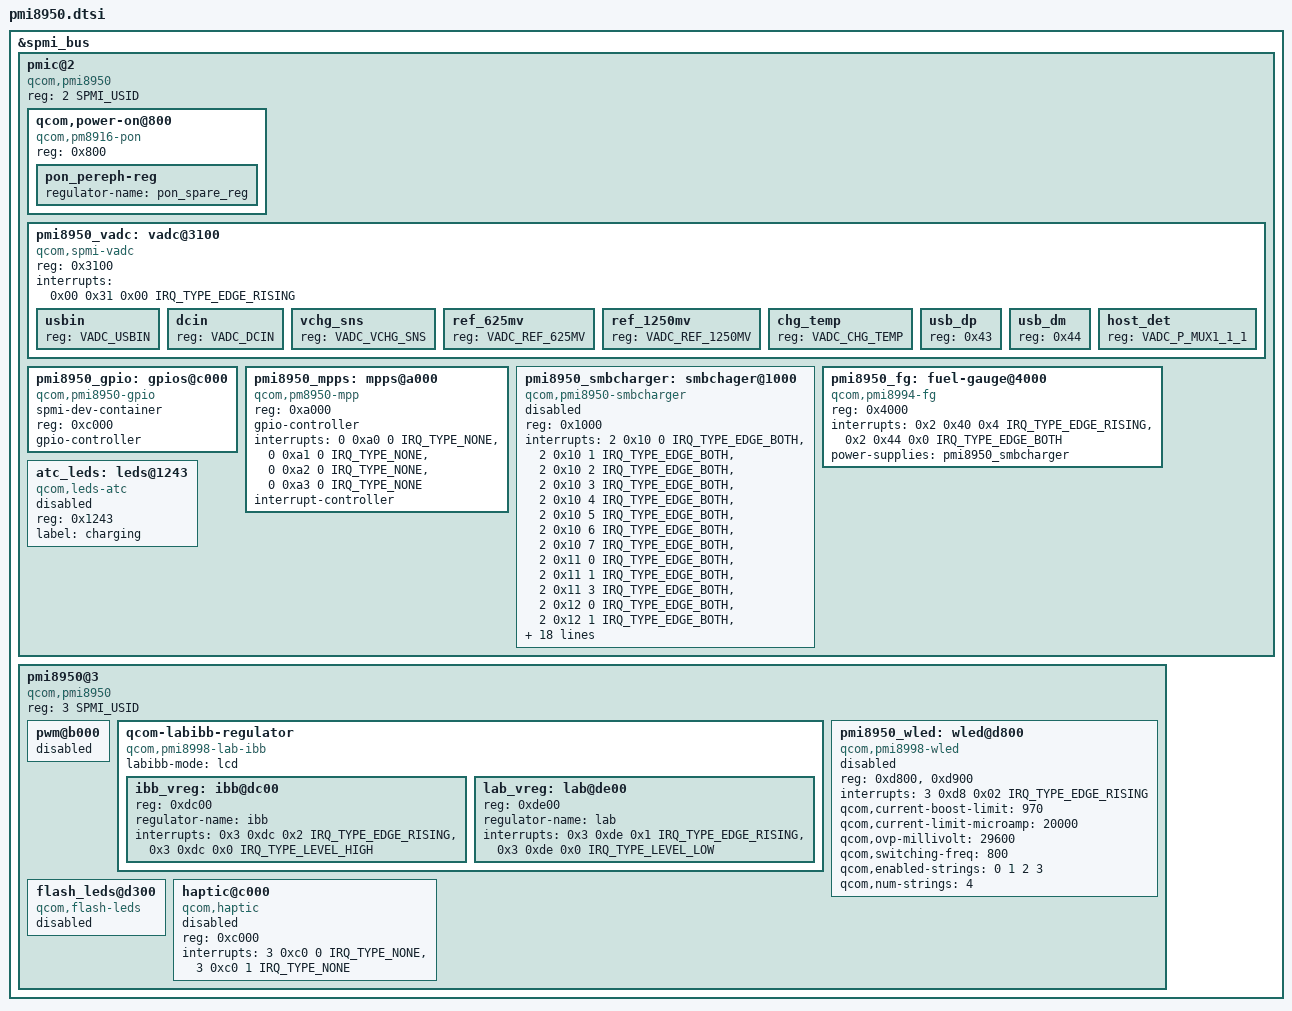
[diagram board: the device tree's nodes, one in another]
// SPDX-License-Identifier: GPL-2.0-only
/* Copyright (c) 2020, The Linux Foundation. All rights reserved.
 */
#include <dt-bindings/iio/qcom,spmi-vadc.h>
#include <dt-bindings/interrupt-controller/irq.h>
#include <dt-bindings/input/linux-event-codes.h>
#include <dt-bindings/spmi/spmi.h>

&spmi_bus {
	pmic@2 {
		compatible = "qcom,pmi8950", "qcom,spmi-pmic";
		reg = <2 SPMI_USID>;
		#address-cells = <1>;
		#size-cells = <0>;

		qcom,power-on@800 {
			compatible = "qcom,pm8916-pon"; //FIXME is this the correct driver
			reg = <0x800>;			//This pmic may be gen2 unlike 8916
			//qcom,secondary-pon-reset;
			//qcom,hard-reset-poweroff-type = <0x04>;
			pon_pereph-reg {
				//TODO:
				regulator-name = "pon_spare_reg";
			};
		};

		pmi8950_vadc: vadc@3100 {
			compatible = "qcom,spmi-vadc";
			reg = <0x3100>;
			interrupts = <0x00 0x31 0x00 IRQ_TYPE_EDGE_RISING>;
			#address-cells = <1>;
			#size-cells = <0>;
			#io-channel-cells = <1>;

			usbin {
				reg = <VADC_USBIN>;
			};

			dcin {
				reg = <VADC_DCIN>;
			};

			vchg_sns {
				reg = <VADC_VCHG_SNS>;
			};

			ref_625mv {
				reg = <VADC_REF_625MV>;
			};

			ref_1250mv {
				reg = <VADC_REF_1250MV>;
			};

			chg_temp {
				reg = <VADC_CHG_TEMP>;
			};

			usb_dp {
				//FIXME: Unsupported?
				reg = <0x43>;
			};

			usb_dm {
				//FIXME: Unsupported?
				reg = <0x44>;
			};

			host_det {
				//FIXME: Unsupported?
				reg = <VADC_P_MUX1_1_1>;
			};
		};

		pmi8950_gpio: gpios@c000 {
			spmi-dev-container;
			compatible = "qcom,pmi8950-gpio";
			reg = <0xc000>;

			gpio-controller;
			#gpio-cells = <2>;
			#address-cells = <1>;
			#size-cells = <0>;
		};

		pmi8950_mpps: mpps@a000 {
			compatible = "qcom,pm8950-mpp";
			reg = <0xa000>;
			gpio-controller;
			#gpio-cells = <2>;
			interrupts = <0 0xa0 0 IRQ_TYPE_NONE>,
				     <0 0xa1 0 IRQ_TYPE_NONE>,
				     <0 0xa2 0 IRQ_TYPE_NONE>,
				     <0 0xa3 0 IRQ_TYPE_NONE>;
			interrupt-controller;
			#interrupt-cells = <2>;
		};

		pmi8950_smbcharger: smbchager@1000 {
			compatible = "qcom,pmi8950-smbcharger";
			reg = <0x1000>;
			status = "disabled";
			interrupts = <2 0x10 0 IRQ_TYPE_EDGE_BOTH>,
					<2 0x10 1 IRQ_TYPE_EDGE_BOTH>,
					<2 0x10 2 IRQ_TYPE_EDGE_BOTH>,
					<2 0x10 3 IRQ_TYPE_EDGE_BOTH>,
					<2 0x10 4 IRQ_TYPE_EDGE_BOTH>,
					<2 0x10 5 IRQ_TYPE_EDGE_BOTH>,
					<2 0x10 6 IRQ_TYPE_EDGE_BOTH>,
					<2 0x10 7 IRQ_TYPE_EDGE_BOTH>,
					<2 0x11 0 IRQ_TYPE_EDGE_BOTH>,
					<2 0x11 1 IRQ_TYPE_EDGE_BOTH>,
					<2 0x11 3 IRQ_TYPE_EDGE_BOTH>,
					<2 0x12 0 IRQ_TYPE_EDGE_BOTH>,
					<2 0x12 1 IRQ_TYPE_EDGE_BOTH>,
					<2 0x12 2 IRQ_TYPE_EDGE_BOTH>,
					<2 0x12 3 IRQ_TYPE_EDGE_BOTH>,
					<2 0x12 4 IRQ_TYPE_EDGE_BOTH>,
					<2 0x12 5 IRQ_TYPE_EDGE_BOTH>,
					<2 0x12 6 IRQ_TYPE_EDGE_BOTH>,
					<2 0x12 7 IRQ_TYPE_EDGE_BOTH>,
					<0x2 0x13 0x0 IRQ_TYPE_EDGE_BOTH>,
					<0x2 0x13 0x1 IRQ_TYPE_EDGE_BOTH>,
					<0x2 0x13 0x2 IRQ_TYPE_EDGE_BOTH>,
					<0x2 0x13 0x5 IRQ_TYPE_EDGE_BOTH>,
					<0x2 0x14 0x0 IRQ_TYPE_EDGE_BOTH>,
					<0x2 0x14 0x1 IRQ_TYPE_EDGE_BOTH>,
					<0x2 0x16 0x0 IRQ_TYPE_EDGE_BOTH>,
					<0x2 0x16 0x1 IRQ_TYPE_EDGE_BOTH>,
					<0x2 0x16 0x2 IRQ_TYPE_EDGE_BOTH>,
					<0x2 0x16 0x3 IRQ_TYPE_EDGE_BOTH>,
					<0x2 0x16 0x4 IRQ_TYPE_EDGE_BOTH>,
					<0x2 0x16 0x5 IRQ_TYPE_EDGE_BOTH>;

			interrupt-names = "chg-error",
					"chg-inhibit",
					"chg-prechg-sft",
					"chg-complete-chg-sft",
					"chg-p2f-thr",
					"chg-rechg-thr",
					"chg-taper-thr",
					"chg-tcc-thr",
					"otg-fail",
					"otg-oc",
					"usbid-change",
					"batt-hot",
					"batt-warm",
					"batt-cold",
					"batt-cool",
					"batt-ov",
					"batt-low",
					"batt-missing",
					"batt-term-missing",
					"usbin-uv",
					"usbin-ov",
					"usbin-src-det",
					"aicl-done",
					"dcin-uv",
					"dcin-ov",
					"power-ok",
					"temp-shutdown",
					"wdog-timeout",
					"flash-fail",
					"otst2",
					"otst3";
		};

		pmi8950_fg: fuel-gauge@4000 {
			compatible = "qcom,pmi8994-fg";
			reg = <0x4000>;

			interrupts = <0x2 0x40 0x4 IRQ_TYPE_EDGE_RISING>,
				     <0x2 0x44 0x0 IRQ_TYPE_EDGE_BOTH>;
			interrupt-names = "soc-delta", "mem-avail";

			power-supplies = <&pmi8950_smbcharger>;
			status = "okay";
		};

		atc_leds: leds@1243 {
			reg = <0x1243>;
			compatible = "qcom,leds-atc";
			label = "charging";
			status = "disabled";
		};
	};

	pmi8950@3 {
		compatible = "qcom,pmi8950", "qcom,spmi-pmic";
		reg = <3 SPMI_USID>;
		#address-cells = <1>;
		#size-cells = <0>;

		pwm@b000 {
			status = "disabled";
		};

		qcom-labibb-regulator {
			compatible = "qcom,pmi8998-lab-ibb";
			labibb-mode = "lcd";
			#address-cells = <1>;
			#size-cells = <0>;

			ibb_vreg: ibb@dc00 {
				reg = <0xdc00>;
				regulator-name = "ibb";
				interrupts = <0x3 0xdc 0x2 IRQ_TYPE_EDGE_RISING>,
					     <0x3 0xdc 0x0 IRQ_TYPE_LEVEL_HIGH>;
				interrupt-names = "sc-err", "ocp";
			};

			lab_vreg: lab@de00 {
				reg = <0xde00>;
				regulator-name = "lab";
				interrupts = <0x3 0xde 0x1 IRQ_TYPE_EDGE_RISING>,
					     <0x3 0xde 0x0 IRQ_TYPE_LEVEL_LOW>;
				interrupt-names = "sc-err", "ocp";
			};
		};

		pmi8950_wled: wled@d800 {
			#address-cells = <1>;
			#size-cells = <0>;

			compatible = "qcom,pmi8998-wled";

			reg = <0xd800>, <0xd900>;

			interrupts = <3 0xd8 0x02 IRQ_TYPE_EDGE_RISING>;
			interrupt-names = "short";

			/*
			 * See Documentation/devicetree/bindings/leds/backlight/qcom-wled.yaml
			 * Corresponding CAF properties in comments.
			 * Recheck if matches and override.
			 */

			/* this settings are also defaults in the driver */
			qcom,current-boost-limit = <970>;	// qcom,ilim-ma
			qcom,current-limit-microamp = <20000>;	// qcom,fs-curr-ua
			qcom,ovp-millivolt = <29600>;		// qcom,ovp-mv
			qcom,switching-freq = <800>;		// qcom,switch-freq-khz
			qcom,enabled-strings = <0 1 2 3>;	// qcom,led-strings-list
			qcom,num-strings = <4>;			// length of qcom,enabled-strings
			// qcom,cabc;				// qcom,en-cabc
			// qcom,eternal-pfet;			// qcom,en-ext-pfet-sc-pro;

			status = "disabled";

		};

		flash_leds@d300 {
			compatible = "qcom,flash-leds";
			status = "disabled";
		};

		haptic@c000 {
			compatible = "qcom,haptic";
			status = "disabled";
			reg = <0xc000>;
			interrupts = <3 0xc0 0 IRQ_TYPE_NONE>,
				<3 0xc0 1 IRQ_TYPE_NONE>;
			interrupt-names = "sc-irq", "play-irq";
		};
	};
};
